# CH32V00xxx register map
Vendor: WCH Ltd.; File version: 1.0
Registers are 32-bit, read-write, reset 0x0 unless marked. A register's access mark holds for its fields unless they carry their own. Offsets are from the block's base; [hi:lo] are bit positions; {n}, {i} and the like mark numbered series.

## DBG — Debug support
Base 0xE000D000
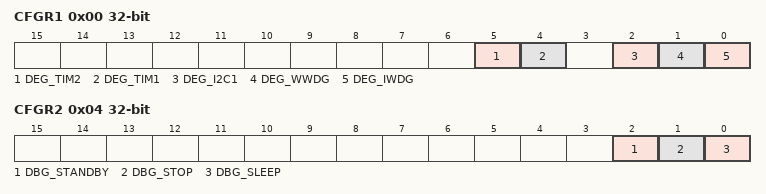
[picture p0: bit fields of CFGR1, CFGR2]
0x00 CFGR1 — DBGMCU_CFGR1
  [5] DEG_TIM2, [4] DEG_TIM1, [2] DEG_I2C1, [1] DEG_WWDG, [0] DEG_IWDG
0x04 CFGR2 — DBGMCU_CFGR2
  [2] DBG_STANDBY, [1] DBG_STOP, [0] DBG_SLEEP

## ESIG — Device electronic signature
Base 0x1FFFF7E0
0x00 FLACAP 16-bit ro — Flash capacity register
  [15:0] FLASHSIZE
{0x4+4i} UNIID{i} ro (i=1..3) — Unique identity {i}
  [31:0] U_ID — Unique identity[{32i-1}:{32i-32}]

## FLASH
Base 0x40022000
0x00 ACTLR — Flash key register
  [0] LATENCY — Number of FLASH wait states
0x04 KEYR wo — Flash key register
  [31:0] KEYR — FPEC key
0x08 OBKEYR wo — Flash option key register
  [31:0] OPTKEY — Option byte key
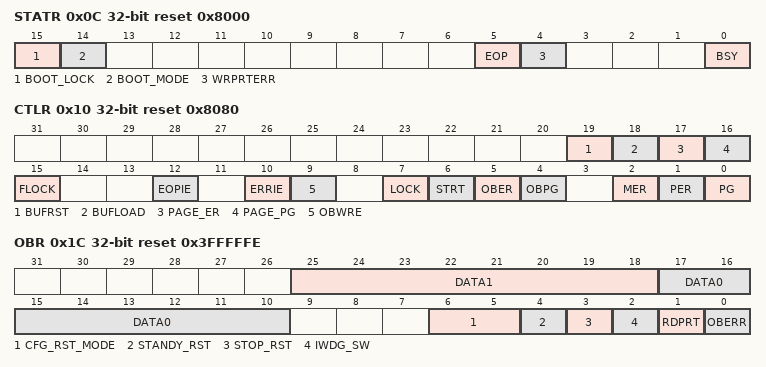
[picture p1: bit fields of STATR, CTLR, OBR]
0x0C STATR access per field reset 0x8000 — Status register
  [15] BOOT_LOCK rw
  [14] BOOT_MODE rw
  [5] EOP rw — End of operation
  [4] WRPRTERR rw — Write protection error
  [0] BSY ro — Busy
0x10 CTLR reset 0x8080 — Control register
  [19] BUFRST — Buffer reset
  [18] BUFLOAD — Buffer load
  [17] PAGE_ER — Fast erase
  [16] PAGE_PG — Fast programming
  [15] FLOCK — Fast programmable lock
  [12] EOPIE — End of operation interrupt enable
  [10] ERRIE — Error interrupt enable
  [9] OBWRE — Option bytes write enable
  [7] LOCK
  [6] STRT — Start
  [5] OBER — Option byte erase
  [4] OBPG — Option byte programming
  [2] MER — Mass Erase
  [1] PER — Page Erase
  [0] PG — Programming
0x14 ADDR wo — Flash address register
  [31:0] ADDR — Flash Address
0x1C OBR ro reset 0x3FFFFFE — Option byte register
  [25:18] DATA1
  [17:10] DATA0
  [6:5] CFG_RST_MODE
  [4] STANDY_RST
  [3] STOP_RST
  [2] IWDG_SW
  [1] RDPRT — Read protection
  [0] OBERR — Option byte error
0x20 WPR ro reset 0xFFFFFFFF — Write protection register
  [31:0] WRP — Write protect
0x24 MODEKEYR wo — Mode select register
  [31:0] MODEKEYR — Mode select
0x28 BOOT_MODEKEYP wo — Boot mode key register
  [31:0] MODEKEYR — Boot mode key

## PFIC — Programmable Fast Interrupt Controller
Base 0xE000E000
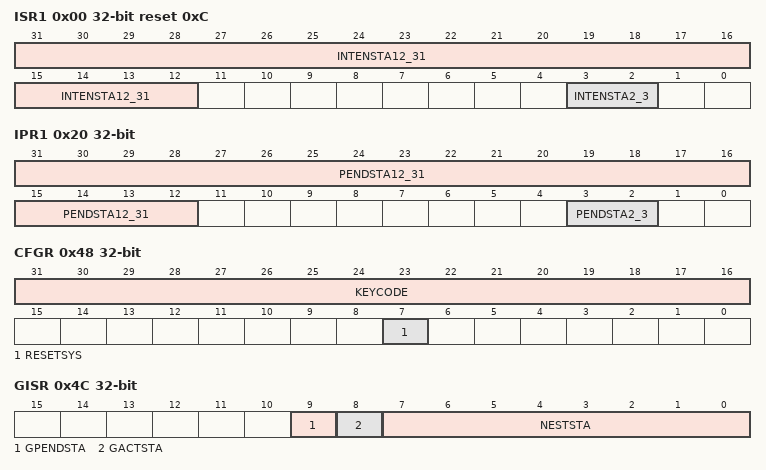
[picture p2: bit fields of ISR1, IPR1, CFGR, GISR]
0x00 ISR1 ro reset 0xC — Interrupt Status Register
  [31:12] INTENSTA12_31 — Interrupt ID Status
  [3:2] INTENSTA2_3 — Interrupt ID Status
0x04 ISR2 ro — Interrupt Status Register
  [31:0] INTENSTA — Interrupt ID Status
0x08 ISR3 ro — Interrupt Status Register
  [31:0] INTENSTA — Interrupt ID Status
0x0C ISR4 ro — Interrupt Status Register
  [7:0] INTENSTA — Interrupt ID Status
0x20 IPR1 ro — Interrupt Pending Register
  [31:12] PENDSTA12_31 — PENDSTA
  [3:2] PENDSTA2_3 — PENDSTA
0x24 IPR2 ro — Interrupt Pending Register
  [31:0] PENDSTA
0x28 IPR3 ro — Interrupt Pending Register
  [31:0] PENDSTA
0x2C IPR4 ro — Interrupt Pending Register
  [7:0] PENDSTA
0x40 ITHRESDR — Interrupt Priority Register
  [7:0] THRESHOLD
0x48 CFGR wo — Interrupt Config Register
  [31:16] KEYCODE, [7] RESETSYS
0x4C GISR ro — Interrupt Global Register
  [9] GPENDSTA, [8] GACTSTA, [7:0] NESTSTA
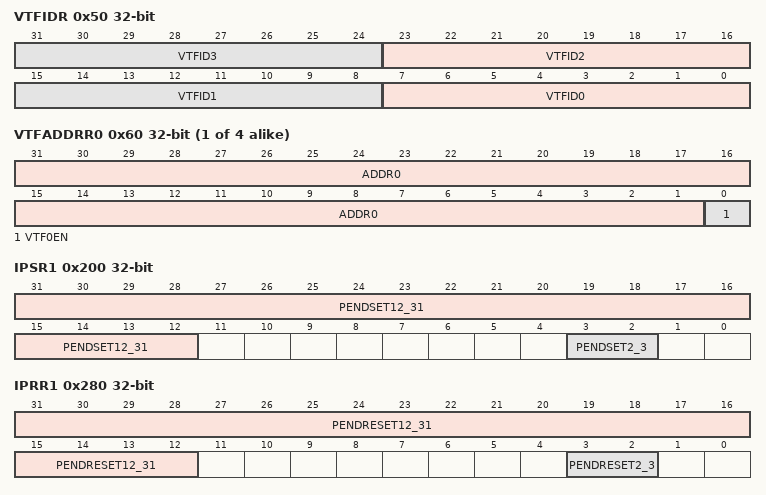
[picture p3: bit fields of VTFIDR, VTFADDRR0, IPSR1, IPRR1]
0x50 VTFIDR — ID Config Register
  [8n+7:8n] VTFID{n} (n=0..3)
{0x60+4i} VTFADDRR{i} (i=0..3) — Interrupt {i} address Register
  [31:1] ADDR{i}, [0] VTF{i}EN
0x100 IENR1 wo — Interrupt Setting Register
  [31:12] INTEN
0x104 IENR2 wo — Interrupt Setting Register
  [31:0] INTEN
0x108 IENR3 wo — Interrupt Setting Register
  [31:0] INTEN
0x10C IENR4 wo — Interrupt Setting Register
  [7:0] INTEN
0x180 IRER1 wo — Interrupt Clear Register
  [31:12] INTRSET
0x184 IRER2 wo — Interrupt Clear Register
  [31:0] INTRSET
0x188 IRER3 wo — Interrupt Clear Register
  [31:0] INTRSET
0x18C IRER4 wo — Interrupt Clear Register
  [7:0] INTRSET
0x200 IPSR1 wo — Interrupt Pending Register
  [31:12] PENDSET12_31 — PENDSET
  [3:2] PENDSET2_3 — PENDSET
0x204 IPSR2 wo — Interrupt Pending Register
  [31:0] PENDSET
0x208 IPSR3 wo — Interrupt Pending Register
  [31:0] PENDSET
0x20C IPSR4 wo — Interrupt Pending Register
  [7:0] PENDSET
0x280 IPRR1 wo — Interrupt Pending Clear Register
  [31:12] PENDRESET12_31 — PENDRESET
  [3:2] PENDRESET2_3 — PENDRESET
0x284 IPRR2 wo — Interrupt Pending Clear Register
  [31:0] PENDRESET
0x288 IPRR3 wo — Interrupt Pending Clear Register
  [31:0] PENDRESET
0x28C IPRR4 wo — Interrupt Pending Clear Register
  [7:0] PENDRESET
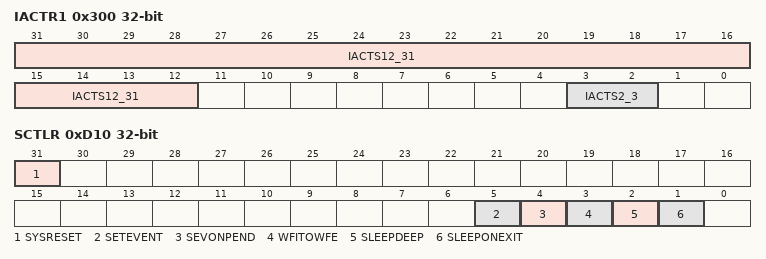
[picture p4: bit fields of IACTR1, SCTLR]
0x300 IACTR1 wo — Interrupt ACTIVE Register
  [31:12] IACTS12_31 — IACTS
  [3:2] IACTS2_3 — IACTS
0x304 IACTR2 wo — Interrupt ACTIVE Register
  [31:0] IACTS
0x308 IACTR3 wo — Interrupt ACTIVE Register
  [31:0] IACTS
0x30C IACTR4 wo — Interrupt ACTIVE Register
  [7:0] IACTS
{0x400+i} IPRIOR{i} 8-bit (i=0..63) — Interrupt Priority Register
0xD10 SCTLR — System Control Register
  [31] SYSRESET, [5] SETEVENT, [4] SEVONPEND, [3] WFITOWFE, [2] SLEEPDEEP, [1] SLEEPONEXIT

## SYSTICK — Systick registers, 32-bit downcounter for QingKeV2
Base 0xE000F000
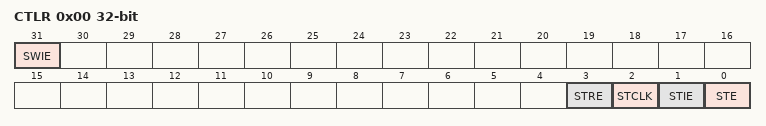
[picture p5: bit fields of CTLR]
0x00 CTLR — System count control register
  [31] SWIE — Software interrupt enable
  [3] STRE — Auto reload count enable bit
  [2] STCLK — Counter system clock sourse selection bit
  [1] STIE — Counter interrupt enable control bit
  [0] STE — Counter enable control bit
0x04 SR — System count status register
  [0] CNTIF — Count value compare flag
0x08 CNT — System counter register
0x10 CMPR — System count compare register
  [31:0] CMP
